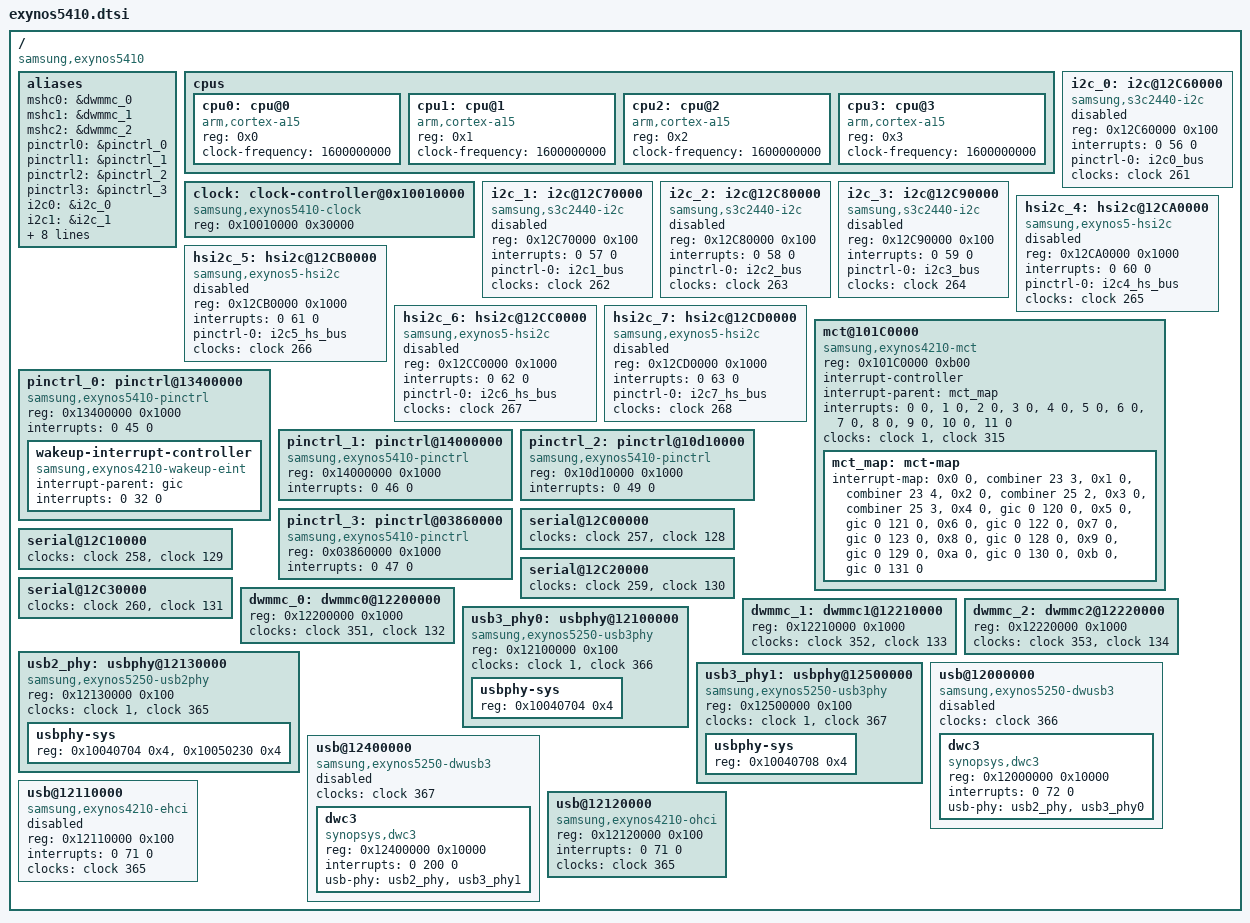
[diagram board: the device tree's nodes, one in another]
/*
 * Hardkernel's Odroid-xu based SAMSUNG EXYNOS5410 SoC device tree source
 *
 * Copyright (c) 2013 Hardkernel Co., Ltd.
 *		http://www.hardkernel.com
 *
 * Hardkernel's Odroid-xu based SAMSUNG EXYNOS5410 SoC device nodes are listed 
 * in this file.
 * EXYNOS5410 based board files can include this file and provide
 * values for board specfic bindings.
 *
 * This program is free software; you can redistribute it and/or modify
 * it under the terms of the GNU General Public License version 2 as
 * published by the Free Software Foundation.
 */

#include "exynos5.dtsi"
/include/ "exynos5410-pinctrl.dtsi"
/ {
	compatible = "samsung,exynos5410";

	aliases {
		mshc0 = &dwmmc_0;
		mshc1 = &dwmmc_1;
		mshc2 = &dwmmc_2;
		pinctrl0 = &pinctrl_0;
		pinctrl1 = &pinctrl_1;
		pinctrl2 = &pinctrl_2;
		pinctrl3 = &pinctrl_3;
		i2c0 = &i2c_0;
		i2c1 = &i2c_1;
		i2c2 = &i2c_2;
		i2c3 = &i2c_3;
		i2c4 = &hsi2c_4;
		i2c5 = &hsi2c_5;
		i2c6 = &hsi2c_6;
		i2c7 = &hsi2c_7;
		usb3phy0 = &usb3_phy0;
		usb3phy1 = &usb3_phy1;
	};

	cpus {
		#address-cells = <1>;
		#size-cells = <0>;

		cpu0: cpu@0 {
			device_type = "cpu";
			compatible = "arm,cortex-a15";
			reg = <0x0>;
			clock-frequency = <1600000000>;
		};

		cpu1: cpu@1 {
			device_type = "cpu";
			compatible = "arm,cortex-a15";
			reg = <0x1>;
			clock-frequency = <1600000000>;
		};

		cpu2: cpu@2 {
			device_type = "cpu";
			compatible = "arm,cortex-a15";
			reg = <0x2>;
			clock-frequency = <1600000000>;
		};

		cpu3: cpu@3 {
			device_type = "cpu";
			compatible = "arm,cortex-a15";
			reg = <0x3>;
			clock-frequency = <1600000000>;
		};
	};

	clock: clock-controller@0x10010000 {
		compatible = "samsung,exynos5410-clock";
		reg = <0x10010000 0x30000>;
		#clock-cells = <1>;
	};

	i2c_0: i2c@12C60000 {
		compatible = "samsung,s3c2440-i2c";
		reg = <0x12C60000 0x100>;
		interrupts = <0 56 0>;
		#address-cells = <1>;
		#size-cells = <0>;
		pinctrl-names = "default";
		pinctrl-0 = <&i2c0_bus>;
		clocks = <&clock 261>;
		clock-names = "i2c";
		status = "disabled";
	};

	i2c_1: i2c@12C70000 {
		compatible = "samsung,s3c2440-i2c";
		reg = <0x12C70000 0x100>;
		interrupts = <0 57 0>;
		#address-cells = <1>;
		#size-cells = <0>;
		pinctrl-names = "default";
		pinctrl-0 = <&i2c1_bus>;
		clocks = <&clock 262>;
		clock-names = "i2c";
		status = "disabled";
	};

	i2c_2: i2c@12C80000 {
		compatible = "samsung,s3c2440-i2c";
		reg = <0x12C80000 0x100>;
		interrupts = <0 58 0>;
		#address-cells = <1>;
		#size-cells = <0>;
		pinctrl-names = "default";
		pinctrl-0 = <&i2c2_bus>;
		clocks = <&clock 263>;
		clock-names = "i2c";
		status = "disabled";
	};

	i2c_3: i2c@12C90000 {
		compatible = "samsung,s3c2440-i2c";
		reg = <0x12C90000 0x100>;
		interrupts = <0 59 0>;
		#address-cells = <1>;
		#size-cells = <0>;
		pinctrl-names = "default";
		pinctrl-0 = <&i2c3_bus>;
		clocks = <&clock 264>;
		clock-names = "i2c";
		status = "disabled";
	};

	hsi2c_4: hsi2c@12CA0000 {
		compatible = "samsung,exynos5-hsi2c";
		reg = <0x12CA0000 0x1000>;
		interrupts = <0 60 0>;
		#address-cells = <1>;
		#size-cells = <0>;
		pinctrl-names = "default";
		pinctrl-0 = <&i2c4_hs_bus>;
		clocks = <&clock 265>;
		clock-names = "hsi2c";
		status = "disabled";
	};

	hsi2c_5: hsi2c@12CB0000 {
		compatible = "samsung,exynos5-hsi2c";
		reg = <0x12CB0000 0x1000>;
		interrupts = <0 61 0>;
		#address-cells = <1>;
		#size-cells = <0>;
		pinctrl-names = "default";
		pinctrl-0 = <&i2c5_hs_bus>;
		clocks = <&clock 266>;
		clock-names = "hsi2c";
		status = "disabled";
	};

	hsi2c_6: hsi2c@12CC0000 {
		compatible = "samsung,exynos5-hsi2c";
		reg = <0x12CC0000 0x1000>;
		interrupts = <0 62 0>;
		#address-cells = <1>;
		#size-cells = <0>;
		pinctrl-names = "default";
		pinctrl-0 = <&i2c6_hs_bus>;
		clocks = <&clock 267>;
		clock-names = "hsi2c";
		status = "disabled";
	};

	hsi2c_7: hsi2c@12CD0000 {
		compatible = "samsung,exynos5-hsi2c";
		reg = <0x12CD0000 0x1000>;
		interrupts = <0 63 0>;
		#address-cells = <1>;
		#size-cells = <0>;
		pinctrl-names = "default";
		pinctrl-0 = <&i2c7_hs_bus>;
		clocks = <&clock 268>;
		clock-names = "hsi2c";
		status = "disabled";
	};

	mct@101C0000 {
		compatible = "samsung,exynos4210-mct";
		reg = <0x101C0000 0xb00>;
		interrupt-controller;
		#interrups-cells = <2>;
		interrupt-parent = <&mct_map>;
		interrupts = <0 0>, <1 0>, <2 0>, <3 0>,
					 <4 0>, <5 0>, <6 0>, <7 0>,
					 <8 0>, <9 0>, <10 0>, <11 0>;
		clocks = <&clock 1>, <&clock 315>;
		clock-names = "fin_pll", "mct";

		mct_map: mct-map {
			#interrupt-cells = <2>;
			#address-cells = <0>;
			#size-cells = <0>;
			interrupt-map = <0x0 0 &combiner 23 3>,
					<0x1 0 &combiner 23 4>,
					<0x2 0 &combiner 25 2>,
					<0x3 0 &combiner 25 3>,
					<0x4 0 &gic 0 120 0>,
					<0x5 0 &gic 0 121 0>,
					<0x6 0 &gic 0 122 0>,
					<0x7 0 &gic 0 123 0>,
					<0x8 0 &gic 0 128 0>,
					<0x9 0 &gic 0 129 0>,
					<0xa 0 &gic 0 130 0>,
					<0xb 0 &gic 0 131 0>;
		};
	};

	pinctrl_0: pinctrl@13400000 {
		compatible = "samsung,exynos5410-pinctrl";
		reg = <0x13400000 0x1000>;
		interrupts = <0 45 0>;

		wakeup-interrupt-controller {
			compatible = "samsung,exynos4210-wakeup-eint";
			interrupt-parent = <&gic>;
			interrupts = <0 32 0>;
		};
	};

	pinctrl_1: pinctrl@14000000 {
		compatible = "samsung,exynos5410-pinctrl";
		reg = <0x14000000 0x1000>;
		interrupts = <0 46 0>;
	};

	pinctrl_2: pinctrl@10d10000 {
		compatible = "samsung,exynos5410-pinctrl";
		reg = <0x10d10000 0x1000>;
		interrupts = <0 49 0>;
	};

	pinctrl_3: pinctrl@03860000 {
		compatible = "samsung,exynos5410-pinctrl";
		reg = <0x03860000 0x1000>;
		interrupts = <0 47 0>;
	};

	serial@12C00000 {
		clocks = <&clock 257>, <&clock 128>;
		clock-names = "uart", "clk_uart_baud0";
	};

	serial@12C10000 {
		clocks = <&clock 258>, <&clock 129>;
		clock-names = "uart", "clk_uart_baud0";
	};

	serial@12C20000 {
		clocks = <&clock 259>, <&clock 130>;
		clock-names = "uart", "clk_uart_baud0";
	};

	serial@12C30000 {
		clocks = <&clock 260>, <&clock 131>;
		clock-names = "uart", "clk_uart_baud0";
	};

	dwmmc_0: dwmmc0@12200000 {
		reg = <0x12200000 0x1000>;
		clocks = <&clock 351>, <&clock 132>;
		clock-names = "biu", "ciu";
	};

	dwmmc_1: dwmmc1@12210000 {
		reg = <0x12210000 0x1000>;
		clocks = <&clock 352>, <&clock 133>;
		clock-names = "biu", "ciu";
	};

	dwmmc_2: dwmmc2@12220000 {
		reg = <0x12220000 0x1000>;
		clocks = <&clock 353>, <&clock 134>;
		clock-names = "biu", "ciu";
	};

	usb2_phy: usbphy@12130000 {
		compatible = "samsung,exynos5250-usb2phy";
		reg = <0x12130000 0x100>;
		clocks = <&clock 1>, <&clock 365>;
		clock-names = "ext_xtal", "usbhost";
		#address-cells = <1>;
		#size-cells = <1>;
		ranges;

		usbphy-sys {
			reg = <0x10040704 0x4>,
				  <0x10050230 0x4>;
		};
	};

	usb3_phy0: usbphy@12100000 {
		compatible = "samsung,exynos5250-usb3phy";
		reg = <0x12100000 0x100>;
		clocks = <&clock 1>, <&clock 366>;
		clock-names = "ext_xtal", "usbdrd30";
		#address-cells = <1>;
		#size-cells = <1>;
		ranges;

		usbphy-sys {
			reg = <0x10040704 0x4>;
		};
	};

	usb3_phy1: usbphy@12500000 {
		compatible = "samsung,exynos5250-usb3phy";
		reg = <0x12500000 0x100>;
		clocks = <&clock 1>, <&clock 367>;
		clock-names = "ext_xtal", "usbdrd30";
		#address-cells = <1>;
		#size-cells = <1>;
		ranges;

		usbphy-sys {
			reg = <0x10040708 0x4>;
		};
	};

	usb@12000000 {
		compatible = "samsung,exynos5250-dwusb3";
		clocks = <&clock 366>;
		clock-names = "usbdrd30";
		#address-cells = <1>;
		#size-cells = <1>;
		ranges;
		status = "disabled";

		dwc3 {
			compatible = "synopsys,dwc3";
			reg = <0x12000000 0x10000>;
			interrupts = <0 72 0>;
			usb-phy = <&usb2_phy &usb3_phy0>;
		};
	};

	usb@12400000 {
		compatible = "samsung,exynos5250-dwusb3";
		clocks = <&clock 367>;
		clock-names = "usbdrd30";
		#address-cells = <1>;
		#size-cells = <1>;
		ranges;
		status = "disabled";

		dwc3 {
			compatible = "synopsys,dwc3";
			reg = <0x12400000 0x10000>;
			interrupts = <0 200 0>;
			usb-phy = <&usb2_phy &usb3_phy1>;
		};
	};

	usb@12110000 {
		compatible = "samsung,exynos4210-ehci";
		reg = <0x12110000 0x100>;
		interrupts = <0 71 0>;
		clocks = <&clock 365>;
		clock-names = "usbhost";
		status = "disabled";
	};

	usb@12120000 {
		compatible = "samsung,exynos4210-ohci";
		reg = <0x12120000 0x100>;
		interrupts = <0 71 0>;
		clocks = <&clock 365>;
		clock-names = "usbhost";
	};
};
